# CM41x_M4 register map
Vendor: Analog Devices; Series: CM41x_M4; File version: 1p0
CPU: CM4 r0p1, little endian, MPU, FPU, 4 interrupt priority bits
Registers are 32-bit, read-write, reset 0x0 unless marked. A register's access mark holds for its fields unless they carry their own. Offsets are from the block's base; [hi:lo] are bit positions; {n}, {i} and the like mark numbered series.

## SCB0 — System Crossbar
Base 0x4F000000
{0x42100+0x1000*i} DMA{i}_RQOS reset 0x1 (i=0..7) — DMA{i} Read Quality of Service Register
  [3:0] VALUE range 0x00000000..0x0000000F — Read Quality of Service
{0x42104+0x1000*i} DMA{i}_WQOS reset 0x1 (i=0..7) — DMA{i} Write Quality of Service Register
  [3:0] VALUE range 0x00000000..0x0000000F — Write Quality of Service
0x4A100 DMA8_RQOS — DMA8 Read Quality of Service Register
  [3:0] VALUE range 0x00000000..0x0000000F — Read Quality of Service
0x4A104 DMA8_WQOS — DMA8 Write Quality of Service Register
  [3:0] VALUE range 0x00000000..0x0000000F — Write Quality of Service
0x4B100 DMA9_RQOS — DMA9 Read Quality of Service Register
  [3:0] VALUE range 0x00000000..0x0000000F — Read Quality of Service
0x4B104 DMA9_WQOS — DMA9 Write Quality of Service Register
  [3:0] VALUE range 0x00000000..0x0000000F — Write Quality of Service
0x4C100 AFE0_RQOS reset 0x1 — AFE0 Read Quality of Service Register
  [3:0] VALUE range 0x00000000..0x0000000F — Read Quality of Service
0x4C104 AFE0_WQOS reset 0x1 — AFE0 Write Quality of Service Register
  [3:0] VALUE range 0x00000000..0x0000000F — Write Quality of Service
0x4D100 FFT0_RQOS reset 0x1 — FFT0 Read Quality of Service Register
  [3:0] VALUE range 0x00000000..0x0000000F — Read Quality of Service
0x4D104 FFT0_WQOS reset 0x1 — FFT0 Write Quality of Service Register
  [3:0] VALUE range 0x00000000..0x0000000F — Write Quality of Service
0x4E100 M4_RQOS reset 0x2 — M4 Core Read Quality of Service Register
  [3:0] VALUE range 0x00000000..0x0000000F — Read Quality of Service
0x4E104 M4_WQOS reset 0x2 — M4 Core Write Quality of Service Register
  [3:0] VALUE range 0x00000000..0x0000000F — Write Quality of Service
0x4F100 M0_RQOS reset 0x3 — M0 Core Read Quality of Service Register
  [3:0] VALUE range 0x00000000..0x0000000F — Read Quality of Service
0x4F104 M0_WQOS reset 0x3 — M0 Core Write Quality of Service Register
  [3:0] VALUE range 0x00000000..0x0000000F — Write Quality of Service
0x51100 SINC0_RQOS reset 0x1 — SINC0 Read Quality of Service Register
  [3:0] VALUE range 0x00000000..0x0000000F — Read Quality of Service
0x51104 SINC0_WQOS reset 0x1 — SINC0 Write Quality of Service Register
  [3:0] VALUE range 0x00000000..0x0000000F — Write Quality of Service

## CXTMC0 — CoreSight TMC
Base 0xE0044000
0x304 FFCR — Formatter and Flush Control Register
  [6] FlushMan_R ro — Manual Flush Completion Status
0xFA0 CLAIMSET reset 0xF — Claim Tag Set Register
  [3:0] CLAIMSET_R ro — Claim Tag Implemented
0xFA4 CLAIMCLR — Claim Tag Clear Register
  [3:0] CLAIMCLR_R ro — Claim Tag Value

## M4P — ARM Cortex-M4 Platform
Base 0xF8008000
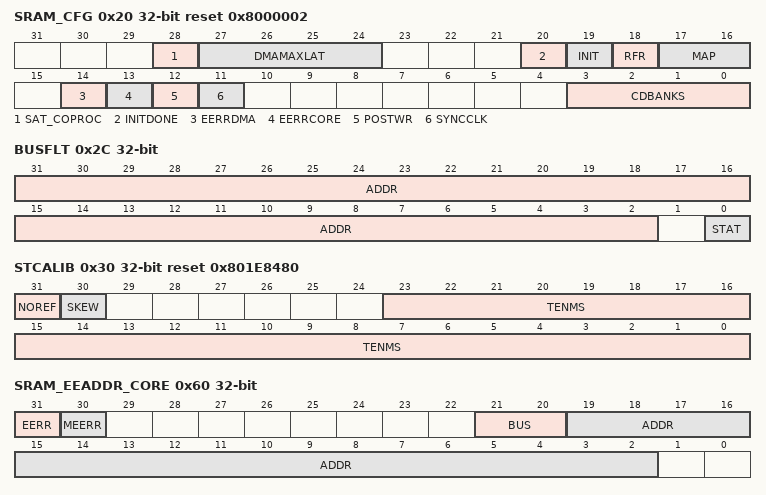
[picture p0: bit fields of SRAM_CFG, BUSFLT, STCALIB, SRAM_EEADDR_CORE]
0x20 SRAM_CFG reset 0x8000002 — SRAM Configuration Register
  [28] SAT_COPROC range 0x00000000..0x00000001 — Enable Saturation Co-processor
  [27:24] DMAMAXLAT range 0x00000000..0x0000000F — DMA Maximum Latency
  [20] INITDONE range 0x00000000..0x00000001 — Enable initialization Done Interrupt
  [19] INIT range 0x00000000..0x00000001 — Enable SRAM Initialization
  [18] RFR range 0x00000000..0x00000001 — Enable SRAM Auto-refresh ECC State
  [17:16] MAP — Enable Accessing the Raw data and ECC Bit in Memory
    0=NORMAL (Normal Operation); 2=ECC_BYPASS_WR_DATA (Map Data); 3=ECC_BYPASS_WR_ECC (Map ECC)
  [14] EERRDMA range 0x00000000..0x00000001 — Enable ECC interrupt, DMA
  [13] EERRCORE range 0x00000000..0x00000001 — Enable ECC interrupt, Core
  [12] POSTWR — Enable Posted System Writes
    0=NORMSYSWRITE (Normal System Writes); 1=POSTSYSWRITE (Posted System Writes)
  [11] SYNCCLK range 0x00000000..0x00000001 — Enable Sync Bypass
  [3:0] CDBANKS — Code/Data Banks Partition
    0=SRAM_CODE_0 (No CODE Config Banks: all assigned to Data); 1=SRAM_CODE_1 (1 CODE config Bank, 4 DATA config banks); 2=SRAM_CODE_2 (2 CODE Config Banks, 3 DATA config banks); 3=SRAM_CODE_3 (3 CODE config Banks, 2 DATA config banks); 4=SRAM_CODE_4 (4 CODE Config Banks, 1 DATA config bank); 5=SRAM_CODE_5 (5 CODE Config Banks, 0 DATA config banks)
0x2C BUSFLT — Bus Fault Error Information Register
  [31:2] ADDR ro — Bus Fault Address
  [0] STAT range 0x00000000..0x00000001 — Bus Fault Status
0x30 STCALIB reset 0x801E8480 — SysTick Calibration Register
  [31] NOREF ro — SysTick Ref Clock Implementation
    0=XREFCLK (SYSTICK External Reference Clock is Implemented); 1=NO_XREFCLK (SYSTICK External Reference Clock is Not Implemented)
  [30] SKEW range 0x00000000..0x00000001 — SysTick Inexact
  [23:0] TENMS range 0x00000000..0x00FFFFFF — SysTick 10ms Calibration
0x5C SRAM_INITDONE — SRAM Initialization Done Status Register
  [0] STAT range 0x00000000..0x00000001 — SRAM Initialization Done Status
0x60 SRAM_EEADDR_CORE — SRAM ECC Error Address (Core) Register
  [31] EERR range 0x00000000..0x00000001 — ECC Error Detected
  [30] MEERR range 0x00000000..0x00000001 — Multiple ECC Error Detected
  [21:20] BUS ro — ECC Bus Interface
    0=IBUS (ECC Error from I-CODE Interface); 1=DBUS (ECC Error from D-Code Interface); 2=SBUS (ECC Error from SYS Interface)
  [19:2] ADDR ro — ECC Error Address
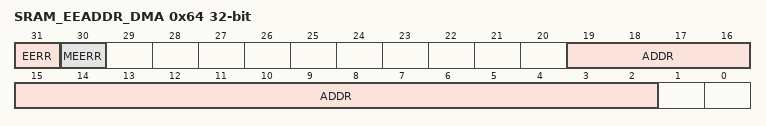
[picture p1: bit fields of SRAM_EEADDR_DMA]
0x64 SRAM_EEADDR_DMA — SRAM ECC Error Address (DMA) Register
  [31] EERR range 0x00000000..0x00000001 — ECC Error Detected
  [30] MEERR range 0x00000000..0x00000001 — Multiple ECC Errors Detected
  [19:2] ADDR ro — ECC Error Address
0x68 SRAM_RFRPER — SRAM Refresh Period Register
  [31:0] VALUE range 0x00000000..0xFFFFFFFF — ECC Memory Auto-refresh Period
0x6C SRAM_RFRADDR — SRAM Refresh Address
  [19:2] VALUE ro — SRAM Auto-refresh Address
0x70 BROMERR — Boot ROM Error Register
  [0] CRCERR range 0x00000000..0x00000001 — BROM CRC Error
